# GD32H7xx register map
File version: 1.0
CPU: CM7 r1p2, little endian, MPU, FPU, 4 interrupt priority bits
Registers are 32-bit, read-write, reset 0x0 unless marked. A register's access mark holds for its fields unless they carry their own. Offsets are from the block's base; [hi:lo] are bit positions; 'fields as' and 'values as' point back to an identical list.

## OSPIM — OSPI I/O Manager
Base 0x5200B400
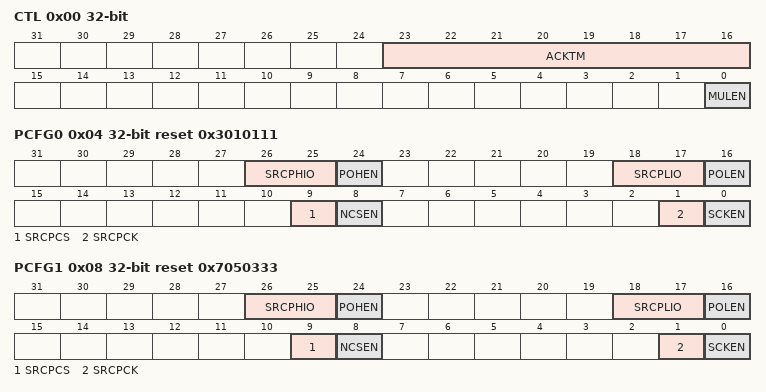
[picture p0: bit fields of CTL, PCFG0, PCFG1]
0x00 CTL — 2Control register
  [23:16] ACKTM — REQ to ACK time
  [0] MULEN — Multiplexed mode enable
0x04 PCFG0 reset 0x3010111 — Port configuration regist 0
  [26:25] SRCPHIO — Source selection for IO[7:4] of port x
  [24] POHEN — Enable for IO[7:4] of port x
  [18:17] SRCPLIO — Source selection for IO[3:0] of port x
  [16] POLEN — Enable for IO[3:0] of port x
  [9] SRCPCS — Source selection for CSN of port x
  [8] NCSEN — Enable for CSN of port x
  [1] SRCPCK — Source selection for SCK of port x
  [0] SCKEN — Enable for SCK of port x
0x08 PCFG1 reset 0x7050333 — Port configuration regist 1
  fields as PCFG0

## OSPI0 — Octal-SPI Interface 0
Base 0x52005000
Same registers: OSPI1 0x5200A000
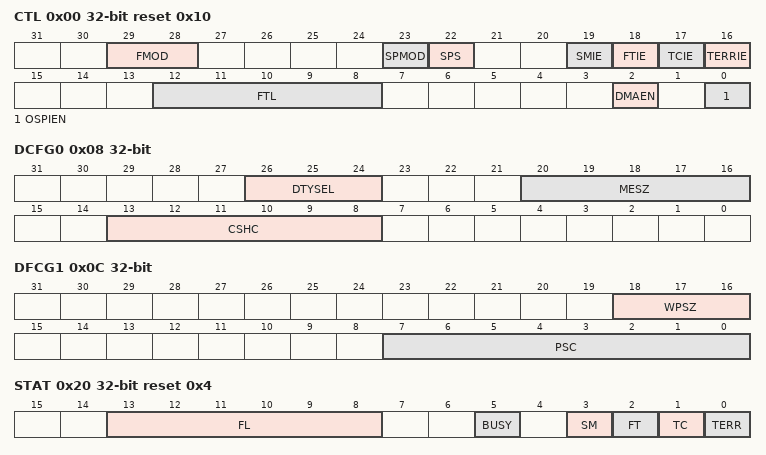
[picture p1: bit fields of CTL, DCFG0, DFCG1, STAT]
0x00 CTL reset 0x10 — Control register
  [29:28] FMOD — Functional mode
  [23] SPMOD — Status polling match mode
  [22] SPS — Status polling mode stop
  [19] SMIE — Status match interrupt enable
  [18] FTIE — FIFO threshold interrupt enable
  [17] TCIE — Transfer complete interrupt enable
  [16] TERRIE — Transfer error interrupt enable
  [12:8] FTL — FIFO threshold level
  [2] DMAEN — DMA enable
  [0] OSPIEN — Enable OSPI
0x08 DCFG0 — Device configuration register 0
  [26:24] DTYSEL — Select device type
  [20:16] MESZ — Memory size
  [13:8] CSHC — Chip select high cycle
0x0C DFCG1 — Device configuration register 1
  [18:16] WPSZ — Wrap size
  [7:0] PSC — This field defines the scaler factor for generating SCK based on the kernel clock (value+1)
0x20 STAT ro reset 0x4 — Status register
  [13:8] FL — FIFO level
  [5] BUSY
  [3] SM — Status match flag
  [2] FT — FIFO threshold flag
  [1] TC — Transfer complete flag
  [0] TERR — Transfer error flag
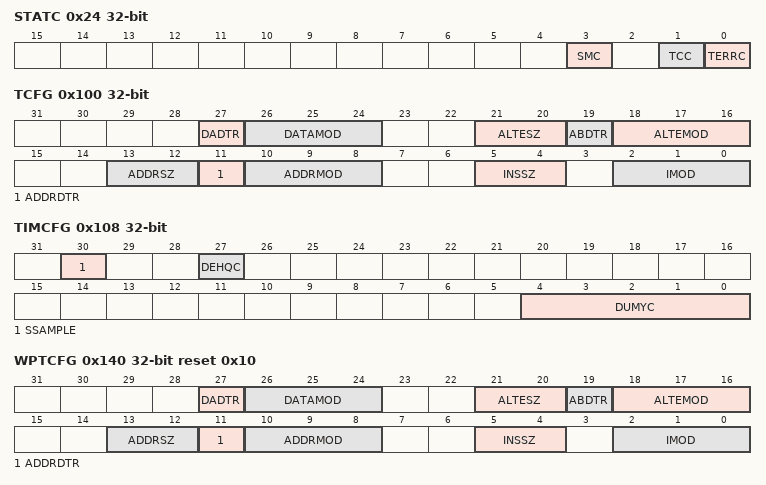
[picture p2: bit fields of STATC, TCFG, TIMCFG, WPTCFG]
0x24 STATC wo — Status clear register
  [3] SMC — Clear status match flag
  [1] TCC — Clear transfer complete flag
  [0] TERRC — Clear transfer error flag
0x40 DTLEN — Data length register
  [31:0] DTLEN — Data length
0x48 ADDR — Address register
  [31:0] ADDR — Address
0x50 DATA
0x80 STATMK — Status mask register
  [31:0] MASK — Status mask
0x88 STATMATCH — Status match register
  [31:0] MATCH — Status match
0x90 INTERVAL
  [15:0] INTERVAL — Interval cycle
0x100 TCFG — Transfer configuration register
  [27] DADTR — Data double transfer rate
  [26:24] DATAMOD — Data mode
  [21:20] ALTESZ — Alternate bytes size
  [19] ABDTR — Alternate bytes double transfer rate
  [18:16] ALTEMOD — Alternate bytes mode
  [13:12] ADDRSZ — Address size
  [11] ADDRDTR — Address double transfer rate
  [10:8] ADDRMOD — Address mode
  [5:4] INSSZ — Instruction size
  [2:0] IMOD — Instruction mode
0x108 TIMCFG — Timing configuration register
  [30] SSAMPLE — Sample shift
  [27] DEHQC — Delay hold 1/4 cycle
  [4:0] DUMYC — Number of dummy cycles
0x110 INS — Instruction register
  [31:0] INSTRUCTION
0x120 ALTE — Alternate bytes register
  [31:0] ALTE — Alternate bytes
0x140 WPTCFG reset 0x10 — Wrap transfer configuration register
  fields as TCFG
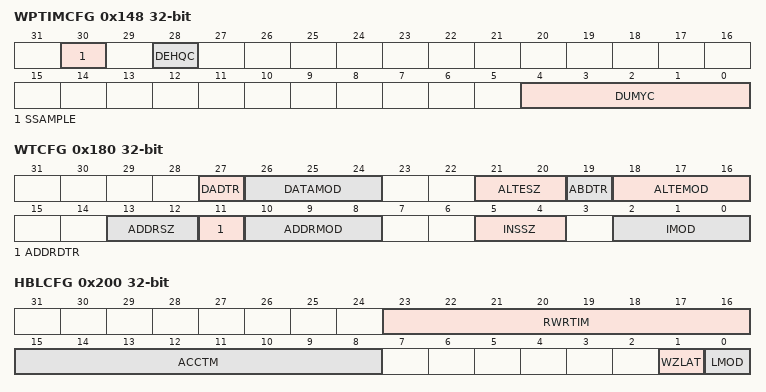
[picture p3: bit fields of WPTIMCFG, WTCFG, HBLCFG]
0x148 WPTIMCFG — Wrap timing configuration register
  [30] SSAMPLE — shift sample
  [28] DEHQC — Delay hold 1/4 cycle
  [4:0] DUMYC — Number of dummy cycles
0x150 WPINS — Wrap instruction register
  [31:0] INSTRUCTION
0x160 WPALTE — Wrap alternate byte register
  [31:0] ALTE — Alternate bytes
0x180 WTCFG — Write transfer configuration register
  [27] DADTR — Data double transfer rate
  [26:24] DATAMOD — data mode
  [21:20] ALTESZ — Alternate bytes size
  [19] ABDTR — Alternate bytes double transfer rate
  [18:16] ALTEMOD — Alternate bytes mode
  [13:12] ADDRSZ — Address size
  [11] ADDRDTR — Alternate bytes double transfer rate
  [10:8] ADDRMOD — address mode
  [5:4] INSSZ — Instruction size
  [2:0] IMOD — Instruction mode
0x188 WTIMCFG reset 0x10 — Write timing configuration register
  [4:0] DUMYC — Number of dummy cycles
0x190 WINS — Write instruction register
  [31:0] INSTRUCTION
0x1A0 WALTE — Write alternate byte register
  [31:0] ALTE — Alternate bytes
0x200 HBLCFG — HyperBus lantency configuration register
  [23:16] RWRTIM — Read write recovery time
  [15:8] ACCTM — Access time
  [1] WZLAT — Write zero latency
  [0] LMOD — Latency mode
